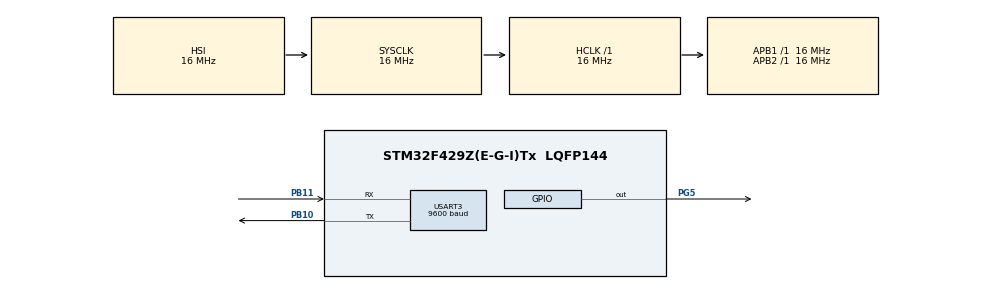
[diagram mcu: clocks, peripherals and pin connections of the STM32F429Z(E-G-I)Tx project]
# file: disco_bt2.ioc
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Mcu.Family=STM32F4
Mcu.Name=STM32F429Z(E-G-I)Tx
Mcu.Package=LQFP144
NVIC.PriorityGroup=NVIC_PRIORITYGROUP_4
NVIC.USART3_IRQn=true\:0\:0\:false\:false\:true
PB10.Mode=Asynchronous
PB10.Signal=USART3_TX
PB11.Mode=Asynchronous
PB11.Signal=USART3_RX
PG5.Signal=GPIO_Output
ProjectManager.HeapSize=0x200
ProjectManager.StackSize=0x400
ProjectManager.TargetToolchain=EWARM
RCC.AHBFreq_Value=16000000
RCC.APB1Freq_Value=16000000
RCC.APB2Freq_Value=16000000
RCC.CortexFreq_Value=16000000
RCC.HSE_VALUE=25000000
RCC.HSI_VALUE=16000000
RCC.LSE_VALUE=32768
RCC.SYSCLKFreq_VALUE=16000000
RCC.VCOOutputFreq_Value=192000000
USART3.BaudRate=9600
board=disco_bt2

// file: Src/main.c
/**
  ******************************************************************************
  * File Name          : main.c
  * Description        : Main program body
  ******************************************************************************
  *
  * COPYRIGHT(c) 2016 STMicroelectronics
  *
  * Redistribution and use in source and binary forms, with or without modification,
  * are permitted provided that the following conditions are met:
  *   1. Redistributions of source code must retain the above copyright notice,
  *      this list of conditions and the following disclaimer.
  *   2. Redistributions in binary form must reproduce the above copyright notice,
  *      this list of conditions and the following disclaimer in the documentation
  *      and/or other materials provided with the distribution.
  *   3. Neither the name of STMicroelectronics nor the names of its contributors
  *      may be used to endorse or promote products derived from this software
  *      without specific prior written permission.
  *
  * THIS SOFTWARE IS PROVIDED BY THE COPYRIGHT HOLDERS AND CONTRIBUTORS "AS IS"
  * AND ANY EXPRESS OR IMPLIED WARRANTIES, INCLUDING, BUT NOT LIMITED TO, THE
  * IMPLIED WARRANTIES OF MERCHANTABILITY AND FITNESS FOR A PARTICULAR PURPOSE ARE
  * DISCLAIMED. IN NO EVENT SHALL THE COPYRIGHT HOLDER OR CONTRIBUTORS BE LIABLE
  * FOR ANY DIRECT, INDIRECT, INCIDENTAL, SPECIAL, EXEMPLARY, OR CONSEQUENTIAL
  * DAMAGES (INCLUDING, BUT NOT LIMITED TO, PROCUREMENT OF SUBSTITUTE GOODS OR
  * SERVICES; LOSS OF USE, DATA, OR PROFITS; OR BUSINESS INTERRUPTION) HOWEVER
  * CAUSED AND ON ANY THEORY OF LIABILITY, WHETHER IN CONTRACT, STRICT LIABILITY,
  * OR TORT (INCLUDING NEGLIGENCE OR OTHERWISE) ARISING IN ANY WAY OUT OF THE USE
  * OF THIS SOFTWARE, EVEN IF ADVISED OF THE POSSIBILITY OF SUCH DAMAGE.
  *
  ******************************************************************************
  */
#include "stm32f4xx_hal.h"

UART_HandleTypeDef huart3;

/* USER CODE BEGIN PV */
/* Private variables ---------------------------------------------------------*/

/* USER CODE END PV */

void SystemClock_Config(void);
void Error_Handler(void);
static void MX_GPIO_Init(void);
static void MX_USART3_UART_Init(void);

/* USER CODE BEGIN PFP */
/* Private function prototypes -----------------------------------------------*/

/* USER CODE END PFP */

int main(void)
{

  /* MCU Configuration----------------------------------------------------------*/

  /* Reset of all peripherals, Initializes the Flash interface and the Systick. */
  HAL_Init();

  /* Configure the system clock */
  SystemClock_Config();

  /* Initialize all configured peripherals */
  MX_GPIO_Init();
  MX_USART3_UART_Init();

  /* USER CODE BEGIN 2 */

  uint8_t data = 0;
  HAL_UART_Receive_IT(&huart3, &data, 1);

  /* USER CODE END 2 */

  /* Infinite loop */
  while (1)
  {

  /* USER CODE BEGIN 3 */

    HAL_Delay(300);

    //  HAL_UART_Transmit_IT(&huart3, message, 4);

    if(huart3.RxXferCount == 0) {

      if (data == 49) {

        HAL_GPIO_WritePin(GPIOG, GPIO_PIN_5, GPIO_PIN_SET);

      } else if (data == 48) {
        HAL_GPIO_WritePin(GPIOG, GPIO_PIN_5, GPIO_PIN_SET);
        for (int i = 0; i < 10; i++)
        {
          HAL_Delay(100);
          HAL_GPIO_TogglePin(GPIOG, GPIO_PIN_5);
        }
        HAL_GPIO_WritePin(GPIOG, GPIO_PIN_5, GPIO_PIN_RESET);

      } else {

        HAL_GPIO_WritePin(GPIOG, GPIO_PIN_5, GPIO_PIN_RESET);

      }

      printf("XData: %i\n", data);
      data = 0;

    }

    HAL_UART_Receive_IT(&huart3, &data, 1);

  }
  /* USER CODE END 3 */

}

/** System Clock Configuration
*/
void SystemClock_Config(void)
{

  RCC_OscInitTypeDef RCC_OscInitStruct;
  RCC_ClkInitTypeDef RCC_ClkInitStruct;

  __HAL_RCC_PWR_CLK_ENABLE();

  __HAL_PWR_VOLTAGESCALING_CONFIG(PWR_REGULATOR_VOLTAGE_SCALE3);

  RCC_OscInitStruct.OscillatorType = RCC_OSCILLATORTYPE_HSI;
  RCC_OscInitStruct.HSIState = RCC_HSI_ON;
  RCC_OscInitStruct.HSICalibrationValue = 16;
  RCC_OscInitStruct.PLL.PLLState = RCC_PLL_NONE;
  if (HAL_RCC_OscConfig(&RCC_OscInitStruct) != HAL_OK)
  {
    Error_Handler();
  }

  RCC_ClkInitStruct.ClockType = RCC_CLOCKTYPE_HCLK|RCC_CLOCKTYPE_SYSCLK
                              |RCC_CLOCKTYPE_PCLK1|RCC_CLOCKTYPE_PCLK2;
  RCC_ClkInitStruct.SYSCLKSource = RCC_SYSCLKSOURCE_HSI;
  RCC_ClkInitStruct.AHBCLKDivider = RCC_SYSCLK_DIV1;
  RCC_ClkInitStruct.APB1CLKDivider = RCC_HCLK_DIV1;
  RCC_ClkInitStruct.APB2CLKDivider = RCC_HCLK_DIV1;
  if (HAL_RCC_ClockConfig(&RCC_ClkInitStruct, FLASH_LATENCY_0) != HAL_OK)
  {
    Error_Handler();
  }

  HAL_SYSTICK_Config(HAL_RCC_GetHCLKFreq()/1000);

  HAL_SYSTICK_CLKSourceConfig(SYSTICK_CLKSOURCE_HCLK);

  /* SysTick_IRQn interrupt configuration */
  HAL_NVIC_SetPriority(SysTick_IRQn, 0, 0);
}

/* USART3 init function */
static void MX_USART3_UART_Init(void)
{

  huart3.Instance = USART3;
  huart3.Init.BaudRate = 9600;
  huart3.Init.WordLength = UART_WORDLENGTH_8B;
  huart3.Init.StopBits = UART_STOPBITS_1;
  huart3.Init.Parity = UART_PARITY_NONE;
  huart3.Init.Mode = UART_MODE_TX_RX;
  huart3.Init.HwFlowCtl = UART_HWCONTROL_NONE;
  huart3.Init.OverSampling = UART_OVERSAMPLING_16;
  if (HAL_UART_Init(&huart3) != HAL_OK)
  {
    Error_Handler();
  }

}

/** Configure pins as
        * Analog
        * Input
        * Output
        * EVENT_OUT
        * EXTI
*/
static void MX_GPIO_Init(void)
{

  GPIO_InitTypeDef GPIO_InitStruct;

  /* GPIO Ports Clock Enable */
  __HAL_RCC_GPIOB_CLK_ENABLE();
  __HAL_RCC_GPIOG_CLK_ENABLE();

  /*Configure GPIO pin Output Level */
  HAL_GPIO_WritePin(GPIOG, GPIO_PIN_5, GPIO_PIN_RESET);

  /*Configure GPIO pin : PG5 */
  GPIO_InitStruct.Pin = GPIO_PIN_5;
  GPIO_InitStruct.Mode = GPIO_MODE_OUTPUT_PP;
  GPIO_InitStruct.Pull = GPIO_NOPULL;
  GPIO_InitStruct.Speed = GPIO_SPEED_FREQ_LOW;
  HAL_GPIO_Init(GPIOG, &GPIO_InitStruct);

}

void Error_Handler(void)
{
  while(1)
  {
  }
}

/************************ (C) COPYRIGHT STMicroelectronics *****END OF FILE****/
